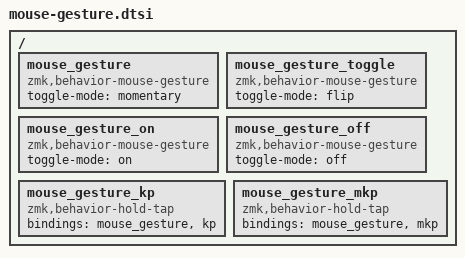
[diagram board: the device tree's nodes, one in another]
/*
 * Copyright (c) 2024 The ZMK Contributors
 *
 * SPDX-License-Identifier: MIT
 */

#include <dt-bindings/zmk/mouse-gesture.h>

/ {
    // mouse_gesture now takes 1 binding cell: the instance_id.
    // Use &mouse_gesture_kp INSTANCE_ID KEY to activate a specific
    // zip_mouse_gesture processor instance on hold, and send KEY on tap.

    /omit-if-no-ref/ mouse_gesture: mouse_gesture {
        compatible = "zmk,behavior-mouse-gesture";
        #binding-cells = <1>;
        toggle-mode = "momentary";
    };

    /omit-if-no-ref/ mouse_gesture_toggle: mouse_gesture_toggle {
        compatible = "zmk,behavior-mouse-gesture";
        #binding-cells = <1>;
        toggle-mode = "flip";
    };

    /omit-if-no-ref/ mouse_gesture_on: mouse_gesture_on {
        compatible = "zmk,behavior-mouse-gesture";
        #binding-cells = <1>;
        toggle-mode = "on";
    };

    /omit-if-no-ref/ mouse_gesture_off: mouse_gesture_off {
        compatible = "zmk,behavior-mouse-gesture";
        #binding-cells = <1>;
        toggle-mode = "off";
    };

    /omit-if-no-ref/ mouse_gesture_kp: mouse_gesture_kp {
        compatible = "zmk,behavior-hold-tap";
        bindings = <&mouse_gesture>, <&kp>;
        #binding-cells = <2>;
    };

    /omit-if-no-ref/ mouse_gesture_mkp: mouse_gesture_mkp {
        compatible = "zmk,behavior-hold-tap";
        bindings = <&mouse_gesture>, <&mkp>;
        #binding-cells = <2>;
    };
};
